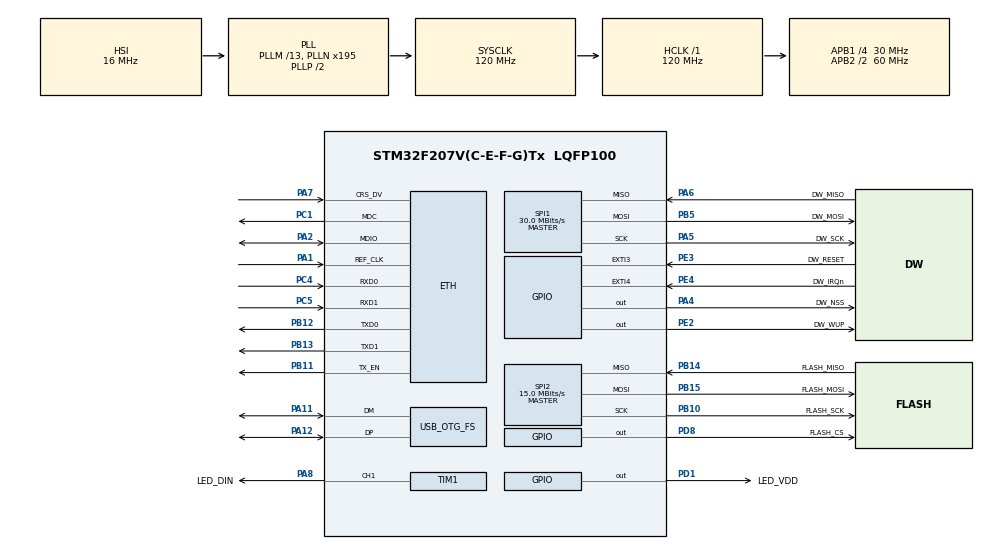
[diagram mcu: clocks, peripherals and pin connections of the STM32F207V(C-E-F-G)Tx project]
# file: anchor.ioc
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Dma.Request0=TIM1_CH1
Dma.TIM1_CH1.0.Direction=DMA_MEMORY_TO_PERIPH
Dma.TIM1_CH1.0.FIFOMode=DMA_FIFOMODE_DISABLE
Dma.TIM1_CH1.0.Instance=DMA2_Stream1
Dma.TIM1_CH1.0.MemDataAlignment=DMA_MDATAALIGN_BYTE
Dma.TIM1_CH1.0.MemInc=DMA_MINC_ENABLE
Dma.TIM1_CH1.0.Mode=DMA_NORMAL
Dma.TIM1_CH1.0.PeriphDataAlignment=DMA_PDATAALIGN_BYTE
Dma.TIM1_CH1.0.PeriphInc=DMA_PINC_DISABLE
Dma.TIM1_CH1.0.Priority=DMA_PRIORITY_LOW
ETH.AutoNegotiation=ETH_AUTONEGOTIATION_ENABLE
ETH.MACAddr=00\:80\:E1\:12\:45\:78
ETH.MediaInterface=ETH_MEDIA_INTERFACE_RMII
ETH.PhyAddress=0
FREERTOS.Tasks01=defaultTask,0,128,StartDefaultTask,Default,NULL
FREERTOS.configTOTAL_HEAP_SIZE=50000
FREERTOS.configUSE_COUNTING_SEMAPHORES=1
LWIP.GATEWAY_ADDRESS=192.168.001.001
LWIP.IP_ADDRESS=192.168.001.100
LWIP.LWIP_DHCP=0
LWIP.MEMP_NUM_TCP_SEG=24
LWIP.NETMASK_ADDRESS=255.255.255.000
LWIP.TCP_SND_BUF=1840
LWIP.TCP_SND_QUEUELEN=17
LWIP.Version=v2.0.3_Cube
Mcu.Family=STM32F2
Mcu.Name=STM32F207V(C-E-F-G)Tx
Mcu.Package=LQFP100
NVIC.DMA2_Stream1_IRQn=true\:5\:0\:false\:false\:true\:true\:false\:true
NVIC.ETH_IRQn=true\:5\:0\:false\:false\:true\:true\:false\:true
NVIC.EXTI3_IRQn=true\:5\:0\:false\:false\:true\:true\:true\:true
NVIC.EXTI4_IRQn=true\:5\:0\:false\:false\:true\:true\:true\:true
NVIC.OTG_FS_IRQn=true\:5\:0\:false\:false\:true\:true\:false\:true
NVIC.PriorityGroup=NVIC_PRIORITYGROUP_4
NVIC.TIM1_UP_TIM10_IRQn=true\:5\:0\:false\:false\:true\:true\:true\:true
NVIC.TIM3_IRQn=true\:0\:0\:false\:false\:true\:false\:false\:true
NVIC.TIM6_DAC_IRQn=true\:5\:0\:false\:false\:true\:true\:true\:true
NVIC.TimeBase=TIM3_IRQn
NVIC.TimeBaseIP=TIM3
PA1.Mode=RMII
PA1.Signal=ETH_REF_CLK
PA11.Mode=Device_Only
PA11.Signal=USB_OTG_FS_DM
PA12.Mode=Device_Only
PA12.Signal=USB_OTG_FS_DP
PA13.Mode=JTAG_5_pins
PA13.Signal=SYS_JTMS-SWDIO
PA14.Mode=JTAG_5_pins
PA14.Signal=SYS_JTCK-SWCLK
PA15.Mode=JTAG_5_pins
PA15.Signal=SYS_JTDI
PA2.Mode=RMII
PA2.Signal=ETH_MDIO
PA4.GPIO_Label=DW_NSS
PA4.PinState=GPIO_PIN_SET
PA4.Signal=GPIO_Output
PA5.GPIO_Label=DW_SCK
PA5.Mode=Full_Duplex_Master
PA5.Signal=SPI1_SCK
PA6.GPIO_Label=DW_MISO
PA6.Mode=Full_Duplex_Master
PA6.Signal=SPI1_MISO
PA7.Mode=RMII
PA7.Signal=ETH_CRS_DV
PA8.GPIO_Label=LED_DIN
PA8.GPIO_Speed=GPIO_SPEED_FREQ_VERY_HIGH
PA8.Signal=S_TIM1_CH1
PB10.GPIO_Label=FLASH_SCK
PB10.Mode=Full_Duplex_Master
PB10.Signal=SPI2_SCK
PB11.Mode=RMII
PB11.Signal=ETH_TX_EN
PB12.Mode=RMII
PB12.Signal=ETH_TXD0
PB13.Mode=RMII
PB13.Signal=ETH_TXD1
PB14.GPIO_Label=FLASH_MISO
PB14.Mode=Full_Duplex_Master
PB14.Signal=SPI2_MISO
PB15.GPIO_Label=FLASH_MOSI
PB15.Mode=Full_Duplex_Master
PB15.Signal=SPI2_MOSI
PB3.Mode=JTAG_5_pins
PB3.Signal=SYS_JTDO-SWO
PB4.Mode=JTAG_5_pins
PB4.Signal=SYS_JTRST
PB5.GPIO_Label=DW_MOSI
PB5.Mode=Full_Duplex_Master
PB5.Signal=SPI1_MOSI
PC1.Mode=RMII
PC1.Signal=ETH_MDC
PC14-OSC32_IN.Mode=LSE-External-Oscillator
PC14-OSC32_IN.Signal=RCC_OSC32_IN
PC15-OSC32_OUT.Mode=LSE-External-Oscillator
PC15-OSC32_OUT.Signal=RCC_OSC32_OUT
PC4.Mode=RMII
PC4.Signal=ETH_RXD0
PC5.Mode=RMII
PC5.Signal=ETH_RXD1
PD1.GPIO_Label=LED_VDD
PD1.Signal=GPIO_Output
PD8.GPIO_Label=FLASH_CS
PD8.Signal=GPIO_Output
PE2.GPIO_Label=DW_WUP
PE2.GPIO_ModeDefaultOutputPP=GPIO_MODE_OUTPUT_OD
PE2.PinState=GPIO_PIN_RESET
PE2.Signal=GPIO_Output
PE3.GPIO_Label=DW_RESET
PE3.Signal=GPXTI3
PE4.GPIO_Label=DW_IRQn
PE4.Signal=GPXTI4
PH0-OSC_IN.Mode=HSE-External-Clock-Source
PH0-OSC_IN.Signal=RCC_OSC_IN
PH1-OSC_OUT.Mode=HSE-External-Clock-Source
PH1-OSC_OUT.Signal=RCC_OSC_OUT
ProjectManager.HeapSize=0x200
ProjectManager.StackSize=0x400
ProjectManager.TargetToolchain=EWARM V8
RCC.48MHZClocksFreq_Value=48000000
RCC.AHBFreq_Value=120000000
RCC.APB1CLKDivider=RCC_HCLK_DIV4
RCC.APB1Freq_Value=30000000
RCC.APB1TimFreq_Value=60000000
RCC.APB2CLKDivider=RCC_HCLK_DIV2
RCC.APB2Freq_Value=60000000
RCC.APB2TimFreq_Value=120000000
RCC.CortexFreq_Value=120000000
RCC.HCLKFreq_Value=120000000
RCC.HSE_VALUE=26000000
RCC.HSI_VALUE=16000000
RCC.PLLM=13
RCC.PLLN=195
RCC.PLLQ=5
RCC.SYSCLKFreq_VALUE=120000000
RCC.SYSCLKSource=RCC_SYSCLKSOURCE_PLLCLK
RCC.VCOOutputFreq_Value=240000000
SH.S_TIM1_CH1.0=TIM1_CH1,PWM Generation1 CH1
SPI1.BaudRatePrescaler=SPI_BAUDRATEPRESCALER_2
SPI1.CalculateBaudRate=30.0 MBits/s
SPI1.Direction=SPI_DIRECTION_2LINES
SPI1.Mode=SPI_MODE_MASTER
SPI1.VirtualType=VM_MASTER
SPI2.BaudRatePrescaler=SPI_BAUDRATEPRESCALER_2
SPI2.CalculateBaudRate=15.0 MBits/s
SPI2.Direction=SPI_DIRECTION_2LINES
SPI2.Mode=SPI_MODE_MASTER
SPI2.VirtualType=VM_MASTER
TIM1.Channel-PWM\ Generation1\ CH1=TIM_CHANNEL_1
TIM1.Period=149
TIM6.AutoReloadPreload=TIM_AUTORELOAD_PRELOAD_ENABLE
TIM6.Prescaler=60
USB_DEVICE.APP_RX_DATA_SIZE-CDC_FS=1000
USB_DEVICE.APP_TX_DATA_SIZE-CDC_FS=1000
USB_DEVICE.CLASS_NAME_FS=CDC
USB_DEVICE.MANUFACTURER_STRING-CDC_FS=POSIT.PRO
USB_DEVICE.PRODUCT_STRING_CDC_FS=AN001 COM
USB_DEVICE.VirtualMode-CDC_FS=Cdc
USB_DEVICE.VirtualModeFS=Cdc_FS
USB_OTG_FS.VirtualMode=Device_Only
VP_FREERTOS_VS_CMSIS_V1.Mode=CMSIS_V1
VP_LWIP_VS_Enabled.Mode=Enabled
VP_SYS_VS_tim3.Mode=TIM3
VP_TIM1_VS_ClockSourceINT.Mode=Internal
VP_TIM6_VS_ClockSourceINT.Mode=Enable_Timer
VP_USB_DEVICE_VS_USB_DEVICE_CDC_FS.Mode=CDC_FS
board=custom

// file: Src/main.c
/* USER CODE BEGIN Header */
/**
  ******************************************************************************
  * @file           : main.c
  * @brief          : Main program body
  ******************************************************************************
  * @attention
  *
  * <h2><center>&copy; Copyright (c) 2019 STMicroelectronics.
  * All rights reserved.</center></h2>
  *
  * This software component is licensed by ST under Ultimate Liberty license
  * SLA0044, the "License"; You may not use this file except in compliance with
  * the License. You may obtain a copy of the License at:
  *                             www.st.com/SLA0044
  *
  ******************************************************************************
  */
/* USER CODE END Header */

#include "main.h"
#include "cmsis_os.h"
#include "lwip.h"
#include "usb_device.h"

SPI_HandleTypeDef hspi1;
SPI_HandleTypeDef hspi2;

TIM_HandleTypeDef htim1;
TIM_HandleTypeDef htim6;
DMA_HandleTypeDef hdma_tim1_ch1;

osThreadId defaultTaskHandle;

void SystemClock_Config(void);
static void MX_GPIO_Init(void);
static void MX_DMA_Init(void);
static void MX_SPI1_Init(void);
static void MX_SPI2_Init(void);
static void MX_TIM6_Init(void);
static void MX_TIM1_Init(void);
void StartDefaultTask(void const * argument);

int main(void)
{

  /* MCU Configuration--------------------------------------------------------*/

  /* Reset of all peripherals, Initializes the Flash interface and the Systick. */
  HAL_Init();

  /* Configure the system clock */
  SystemClock_Config();

  /* Initialize all configured peripherals */
  MX_GPIO_Init();
  MX_DMA_Init();
  MX_SPI1_Init();
  MX_SPI2_Init();
  MX_TIM6_Init();
  MX_TIM1_Init();

  /* Create the thread(s) */
  /* definition and creation of defaultTask */
  osThreadDef(defaultTask, StartDefaultTask, osPriorityNormal, 0, 128);
  defaultTaskHandle = osThreadCreate(osThread(defaultTask), NULL);

  /* Start scheduler */
  osKernelStart();

  /* We should never get here as control is now taken by the scheduler */

  /* Infinite loop */
  while (1)
  {

  }
}

void SystemClock_Config(void)
{
  RCC_OscInitTypeDef RCC_OscInitStruct = {0};
  RCC_ClkInitTypeDef RCC_ClkInitStruct = {0};

  /** Initializes the CPU, AHB and APB busses clocks
  */
  RCC_OscInitStruct.OscillatorType = RCC_OSCILLATORTYPE_HSI;
  RCC_OscInitStruct.HSIState = RCC_HSI_ON;
  RCC_OscInitStruct.HSICalibrationValue = RCC_HSICALIBRATION_DEFAULT;
  RCC_OscInitStruct.PLL.PLLState = RCC_PLL_ON;
  RCC_OscInitStruct.PLL.PLLSource = RCC_PLLSOURCE_HSI;
  RCC_OscInitStruct.PLL.PLLM = 13;
  RCC_OscInitStruct.PLL.PLLN = 195;
  RCC_OscInitStruct.PLL.PLLP = RCC_PLLP_DIV2;
  RCC_OscInitStruct.PLL.PLLQ = 5;
  if (HAL_RCC_OscConfig(&RCC_OscInitStruct) != HAL_OK)
  {
    Error_Handler();
  }
  /** Initializes the CPU, AHB and APB busses clocks
  */
  RCC_ClkInitStruct.ClockType = RCC_CLOCKTYPE_HCLK|RCC_CLOCKTYPE_SYSCLK
                              |RCC_CLOCKTYPE_PCLK1|RCC_CLOCKTYPE_PCLK2;
  RCC_ClkInitStruct.SYSCLKSource = RCC_SYSCLKSOURCE_PLLCLK;
  RCC_ClkInitStruct.AHBCLKDivider = RCC_SYSCLK_DIV1;
  RCC_ClkInitStruct.APB1CLKDivider = RCC_HCLK_DIV4;
  RCC_ClkInitStruct.APB2CLKDivider = RCC_HCLK_DIV2;

  if (HAL_RCC_ClockConfig(&RCC_ClkInitStruct, FLASH_LATENCY_3) != HAL_OK)
  {
    Error_Handler();
  }
}

static void MX_SPI1_Init(void)
{

  /* SPI1 parameter configuration*/
  hspi1.Instance = SPI1;
  hspi1.Init.Mode = SPI_MODE_MASTER;
  hspi1.Init.Direction = SPI_DIRECTION_2LINES;
  hspi1.Init.DataSize = SPI_DATASIZE_8BIT;
  hspi1.Init.CLKPolarity = SPI_POLARITY_LOW;
  hspi1.Init.CLKPhase = SPI_PHASE_1EDGE;
  hspi1.Init.NSS = SPI_NSS_SOFT;
  hspi1.Init.BaudRatePrescaler = SPI_BAUDRATEPRESCALER_2;
  hspi1.Init.FirstBit = SPI_FIRSTBIT_MSB;
  hspi1.Init.TIMode = SPI_TIMODE_DISABLE;
  hspi1.Init.CRCCalculation = SPI_CRCCALCULATION_DISABLE;
  hspi1.Init.CRCPolynomial = 10;
  if (HAL_SPI_Init(&hspi1) != HAL_OK)
  {
    Error_Handler();
  }

}

static void MX_SPI2_Init(void)
{

  /* SPI2 parameter configuration*/
  hspi2.Instance = SPI2;
  hspi2.Init.Mode = SPI_MODE_MASTER;
  hspi2.Init.Direction = SPI_DIRECTION_2LINES;
  hspi2.Init.DataSize = SPI_DATASIZE_8BIT;
  hspi2.Init.CLKPolarity = SPI_POLARITY_LOW;
  hspi2.Init.CLKPhase = SPI_PHASE_1EDGE;
  hspi2.Init.NSS = SPI_NSS_SOFT;
  hspi2.Init.BaudRatePrescaler = SPI_BAUDRATEPRESCALER_2;
  hspi2.Init.FirstBit = SPI_FIRSTBIT_MSB;
  hspi2.Init.TIMode = SPI_TIMODE_DISABLE;
  hspi2.Init.CRCCalculation = SPI_CRCCALCULATION_DISABLE;
  hspi2.Init.CRCPolynomial = 10;
  if (HAL_SPI_Init(&hspi2) != HAL_OK)
  {
    Error_Handler();
  }

}

static void MX_TIM1_Init(void)
{

  TIM_ClockConfigTypeDef sClockSourceConfig = {0};
  TIM_MasterConfigTypeDef sMasterConfig = {0};
  TIM_OC_InitTypeDef sConfigOC = {0};
  TIM_BreakDeadTimeConfigTypeDef sBreakDeadTimeConfig = {0};

  htim1.Instance = TIM1;
  htim1.Init.Prescaler = 0;
  htim1.Init.CounterMode = TIM_COUNTERMODE_UP;
  htim1.Init.Period = 149;
  htim1.Init.ClockDivision = TIM_CLOCKDIVISION_DIV1;
  htim1.Init.RepetitionCounter = 0;
  htim1.Init.AutoReloadPreload = TIM_AUTORELOAD_PRELOAD_DISABLE;
  if (HAL_TIM_Base_Init(&htim1) != HAL_OK)
  {
    Error_Handler();
  }
  sClockSourceConfig.ClockSource = TIM_CLOCKSOURCE_INTERNAL;
  if (HAL_TIM_ConfigClockSource(&htim1, &sClockSourceConfig) != HAL_OK)
  {
    Error_Handler();
  }
  if (HAL_TIM_PWM_Init(&htim1) != HAL_OK)
  {
    Error_Handler();
  }
  sMasterConfig.MasterOutputTrigger = TIM_TRGO_RESET;
  sMasterConfig.MasterSlaveMode = TIM_MASTERSLAVEMODE_DISABLE;
  if (HAL_TIMEx_MasterConfigSynchronization(&htim1, &sMasterConfig) != HAL_OK)
  {
    Error_Handler();
  }
  sConfigOC.OCMode = TIM_OCMODE_PWM1;
  sConfigOC.Pulse = 0;
  sConfigOC.OCPolarity = TIM_OCPOLARITY_HIGH;
  sConfigOC.OCNPolarity = TIM_OCNPOLARITY_HIGH;
  sConfigOC.OCFastMode = TIM_OCFAST_DISABLE;
  sConfigOC.OCIdleState = TIM_OCIDLESTATE_RESET;
  sConfigOC.OCNIdleState = TIM_OCNIDLESTATE_RESET;
  if (HAL_TIM_PWM_ConfigChannel(&htim1, &sConfigOC, TIM_CHANNEL_1) != HAL_OK)
  {
    Error_Handler();
  }
  sBreakDeadTimeConfig.OffStateRunMode = TIM_OSSR_DISABLE;
  sBreakDeadTimeConfig.OffStateIDLEMode = TIM_OSSI_DISABLE;
  sBreakDeadTimeConfig.LockLevel = TIM_LOCKLEVEL_OFF;
  sBreakDeadTimeConfig.DeadTime = 0;
  sBreakDeadTimeConfig.BreakState = TIM_BREAK_DISABLE;
  sBreakDeadTimeConfig.BreakPolarity = TIM_BREAKPOLARITY_HIGH;
  sBreakDeadTimeConfig.AutomaticOutput = TIM_AUTOMATICOUTPUT_DISABLE;
  if (HAL_TIMEx_ConfigBreakDeadTime(&htim1, &sBreakDeadTimeConfig) != HAL_OK)
  {
    Error_Handler();
  }
  HAL_TIM_MspPostInit(&htim1);

}

static void MX_TIM6_Init(void)
{

  TIM_MasterConfigTypeDef sMasterConfig = {0};

  htim6.Instance = TIM6;
  htim6.Init.Prescaler = 60;
  htim6.Init.CounterMode = TIM_COUNTERMODE_UP;
  htim6.Init.Period = 0;
  htim6.Init.AutoReloadPreload = TIM_AUTORELOAD_PRELOAD_ENABLE;
  if (HAL_TIM_Base_Init(&htim6) != HAL_OK)
  {
    Error_Handler();
  }
  sMasterConfig.MasterOutputTrigger = TIM_TRGO_RESET;
  sMasterConfig.MasterSlaveMode = TIM_MASTERSLAVEMODE_DISABLE;
  if (HAL_TIMEx_MasterConfigSynchronization(&htim6, &sMasterConfig) != HAL_OK)
  {
    Error_Handler();
  }

}

static void MX_DMA_Init(void)
{

  /* DMA controller clock enable */
  __HAL_RCC_DMA2_CLK_ENABLE();

  /* DMA interrupt init */
  /* DMA2_Stream1_IRQn interrupt configuration */
  HAL_NVIC_SetPriority(DMA2_Stream1_IRQn, 5, 0);
  HAL_NVIC_EnableIRQ(DMA2_Stream1_IRQn);

}

static void MX_GPIO_Init(void)
{
  GPIO_InitTypeDef GPIO_InitStruct = {0};

  /* GPIO Ports Clock Enable */
  __HAL_RCC_GPIOE_CLK_ENABLE();
  __HAL_RCC_GPIOC_CLK_ENABLE();
  __HAL_RCC_GPIOH_CLK_ENABLE();
  __HAL_RCC_GPIOA_CLK_ENABLE();
  __HAL_RCC_GPIOB_CLK_ENABLE();
  __HAL_RCC_GPIOD_CLK_ENABLE();

  /*Configure GPIO pin Output Level */
  HAL_GPIO_WritePin(DW_WUP_GPIO_Port, DW_WUP_Pin, GPIO_PIN_RESET);

  /*Configure GPIO pin Output Level */
  HAL_GPIO_WritePin(DW_NSS_GPIO_Port, DW_NSS_Pin, GPIO_PIN_SET);

  /*Configure GPIO pin Output Level */
  HAL_GPIO_WritePin(GPIOD, FLASH_CS_Pin|LED_VDD_Pin, GPIO_PIN_RESET);

  /*Configure GPIO pin : DW_WUP_Pin */
  GPIO_InitStruct.Pin = DW_WUP_Pin;
  GPIO_InitStruct.Mode = GPIO_MODE_OUTPUT_OD;
  GPIO_InitStruct.Pull = GPIO_NOPULL;
  GPIO_InitStruct.Speed = GPIO_SPEED_FREQ_LOW;
  HAL_GPIO_Init(DW_WUP_GPIO_Port, &GPIO_InitStruct);

  /*Configure GPIO pins : DW_RESET_Pin DW_IRQn_Pin */
  GPIO_InitStruct.Pin = DW_RESET_Pin|DW_IRQn_Pin;
  GPIO_InitStruct.Mode = GPIO_MODE_IT_RISING;
  GPIO_InitStruct.Pull = GPIO_NOPULL;
  HAL_GPIO_Init(GPIOE, &GPIO_InitStruct);

  /*Configure GPIO pin : DW_NSS_Pin */
  GPIO_InitStruct.Pin = DW_NSS_Pin;
  GPIO_InitStruct.Mode = GPIO_MODE_OUTPUT_PP;
  GPIO_InitStruct.Pull = GPIO_NOPULL;
  GPIO_InitStruct.Speed = GPIO_SPEED_FREQ_LOW;
  HAL_GPIO_Init(DW_NSS_GPIO_Port, &GPIO_InitStruct);

  /*Configure GPIO pins : FLASH_CS_Pin LED_VDD_Pin */
  GPIO_InitStruct.Pin = FLASH_CS_Pin|LED_VDD_Pin;
  GPIO_InitStruct.Mode = GPIO_MODE_OUTPUT_PP;
  GPIO_InitStruct.Pull = GPIO_NOPULL;
  GPIO_InitStruct.Speed = GPIO_SPEED_FREQ_LOW;
  HAL_GPIO_Init(GPIOD, &GPIO_InitStruct);

  /* EXTI interrupt init*/
  HAL_NVIC_SetPriority(EXTI3_IRQn, 5, 0);
  HAL_NVIC_EnableIRQ(EXTI3_IRQn);

  HAL_NVIC_SetPriority(EXTI4_IRQn, 5, 0);
  HAL_NVIC_EnableIRQ(EXTI4_IRQn);

}

void StartDefaultTask(void const * argument)
{
  /* init code for LWIP */
  MX_LWIP_Init();

  /* init code for USB_DEVICE */
  MX_USB_DEVICE_Init();
  /* USER CODE BEGIN 5 */
  /* Infinite loop */
  for(;;)
  {
    osDelay(1000);
//    HAL_GPIO_WritePin(LED1_GPIO_Port, LED1_Pin, GPIO_PIN_RESET);
    HAL_GPIO_WritePin(LED2_GPIO_Port, LED2_Pin, GPIO_PIN_RESET);
//    HAL_GPIO_WritePin(LED3_GPIO_Port, LED3_Pin, GPIO_PIN_RESET);
    osDelay(1000);
//    HAL_GPIO_WritePin(LED1_GPIO_Port, LED1_Pin, GPIO_PIN_SET);
    HAL_GPIO_WritePin(LED2_GPIO_Port, LED2_Pin, GPIO_PIN_SET);
//    HAL_GPIO_WritePin(LED3_GPIO_Port, LED3_Pin, GPIO_PIN_SET);
  }
  /* USER CODE END 5 */
}

void HAL_TIM_PeriodElapsedCallback(TIM_HandleTypeDef *htim)
{
  if (htim->Instance == TIM3) {
    HAL_IncTick();
  }
}

void Error_Handler(void)
{
}

/************************ (C) COPYRIGHT STMicroelectronics *****END OF FILE****/
